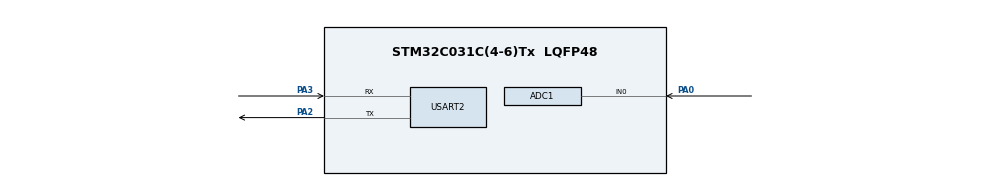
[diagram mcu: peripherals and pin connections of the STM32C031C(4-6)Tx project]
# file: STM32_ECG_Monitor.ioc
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ADC1.NbrOfConversionFlag=0
ADC1.SamplingTimeCommon1=ADC_SAMPLETIME_12CYCLES_5
ADC1.SelectedChannel=ADC_CHANNEL_0
ADC1.master=1
Mcu.Family=STM32C0
Mcu.Name=STM32C031C(4-6)Tx
Mcu.Package=LQFP48
NVIC.TIM3_IRQn=true\:0\:0\:false\:false\:true\:true\:true\:true
PA0.Mode=IN0
PA0.Signal=ADC1_IN0
PA2.Mode=Asynchronous
PA2.Signal=USART2_TX
PA3.Mode=Asynchronous
PA3.Signal=USART2_RX
ProjectManager.HeapSize=0x200
ProjectManager.StackSize=0x400
ProjectManager.TargetToolchain=STM32CubeIDE
RCC.ADCFreq_Value=12000000
RCC.AHBFreq_Value=12000000
RCC.CortexFreq_Value=12000000
RCC.EXTERNAL_CLOCK_VALUE=12288000
RCC.HCLKFreq_Value=12000000
RCC.HSE_VALUE=8000000
RCC.HSI_VALUE=48000000
RCC.LSE_VALUE=32768
RCC.SYSCLKFreq_VALUE=12000000
TIM3.Period=999
TIM3.Prescaler=47
USART2.VirtualMode-Asynchronous=VM_ASYNC
VP_TIM3_VS_ClockSourceINT.Mode=Internal
board=custom

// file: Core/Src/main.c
/* USER CODE BEGIN Header */
/**
  ******************************************************************************
  * @file           : main.c
  * @brief          : Main program body
  ******************************************************************************
  * @attention
  *
  * Copyright (c) 2026 STMicroelectronics.
  * All rights reserved.
  *
  * This software is licensed under terms that can be found in the LICENSE file
  * in the root directory of this software component.
  * If no LICENSE file comes with this software, it is provided AS-IS.
  *
  ******************************************************************************
  */
/* USER CODE END Header */
#include "main.h"

/* USER CODE BEGIN Includes */
#include <stdio.h>
/* USER CODE END Includes */

ADC_HandleTypeDef hadc1;

TIM_HandleTypeDef htim3;

UART_HandleTypeDef huart2;

/* USER CODE BEGIN PV */

/* USER CODE BEGIN PV */

/* USER CODE BEGIN PV */

volatile uint16_t adc_value = 0;
volatile uint8_t sample_ready = 0;

char uart_buffer[32];
int uart_length;

/* USER CODE END PV */

/* USER CODE END PV */

/* USER CODE END PV */

void SystemClock_Config(void);
static void MX_GPIO_Init(void);
static void MX_ADC1_Init(void);
static void MX_TIM3_Init(void);
static void MX_USART2_UART_Init(void);

int main(void)
{

  /* MCU Configuration--------------------------------------------------------*/

  /* Reset of all peripherals, Initializes the Flash interface and the Systick. */
  HAL_Init();

  /* Configure the system clock */
  SystemClock_Config();

  /* Initialize all configured peripherals */
  MX_GPIO_Init();
  MX_ADC1_Init();
  MX_TIM3_Init();
  MX_USART2_UART_Init();
  /* USER CODE BEGIN 2 */

  HAL_TIM_Base_Start_IT(&htim3);

  /* USER CODE END 2 */

  /* Infinite loop */
  while (1)
  {

      /* USER CODE BEGIN 3 */

      if (sample_ready)
      {
          sample_ready = 0;

          HAL_ADC_Start(&hadc1);

          if (HAL_ADC_PollForConversion(&hadc1, 10) == HAL_OK)
          {
              adc_value = HAL_ADC_GetValue(&hadc1);
              uart_length = snprintf(uart_buffer,
                                     sizeof(uart_buffer),
                                     "%u\r\n",
                                     adc_value);

              HAL_UART_Transmit(&huart2,
                                (uint8_t *)uart_buffer,
                                uart_length,
                                HAL_MAX_DELAY);
          }

          HAL_ADC_Stop(&hadc1);
      }
  }
}

void SystemClock_Config(void)
{
  RCC_OscInitTypeDef RCC_OscInitStruct = {0};
  RCC_ClkInitTypeDef RCC_ClkInitStruct = {0};

  __HAL_FLASH_SET_LATENCY(FLASH_LATENCY_0);

  /** Initializes the RCC Oscillators according to the specified parameters
  * in the RCC_OscInitTypeDef structure.
  */
  RCC_OscInitStruct.OscillatorType = RCC_OSCILLATORTYPE_HSI;
  RCC_OscInitStruct.HSIState = RCC_HSI_ON;
  RCC_OscInitStruct.HSIDiv = RCC_HSI_DIV4;
  RCC_OscInitStruct.HSICalibrationValue = RCC_HSICALIBRATION_DEFAULT;
  if (HAL_RCC_OscConfig(&RCC_OscInitStruct) != HAL_OK)
  {
    Error_Handler();
  }

  /** Initializes the CPU, AHB and APB buses clocks
  */
  RCC_ClkInitStruct.ClockType = RCC_CLOCKTYPE_HCLK|RCC_CLOCKTYPE_SYSCLK
                              |RCC_CLOCKTYPE_PCLK1;
  RCC_ClkInitStruct.SYSCLKSource = RCC_SYSCLKSOURCE_HSI;
  RCC_ClkInitStruct.SYSCLKDivider = RCC_SYSCLK_DIV1;
  RCC_ClkInitStruct.AHBCLKDivider = RCC_HCLK_DIV1;
  RCC_ClkInitStruct.APB1CLKDivider = RCC_APB1_DIV1;

  if (HAL_RCC_ClockConfig(&RCC_ClkInitStruct, FLASH_LATENCY_0) != HAL_OK)
  {
    Error_Handler();
  }
}

static void MX_ADC1_Init(void)
{

  ADC_ChannelConfTypeDef sConfig = {0};

  /** Configure the global features of the ADC (Clock, Resolution, Data Alignment and number of conversion)
  */
  hadc1.Instance = ADC1;
  hadc1.Init.ClockPrescaler = ADC_CLOCK_SYNC_PCLK_DIV1;
  hadc1.Init.Resolution = ADC_RESOLUTION_12B;
  hadc1.Init.DataAlign = ADC_DATAALIGN_RIGHT;
  hadc1.Init.ScanConvMode = ADC_SCAN_SEQ_FIXED;
  hadc1.Init.EOCSelection = ADC_EOC_SINGLE_CONV;
  hadc1.Init.LowPowerAutoWait = DISABLE;
  hadc1.Init.LowPowerAutoPowerOff = DISABLE;
  hadc1.Init.ContinuousConvMode = DISABLE;
  hadc1.Init.NbrOfConversion = 1;
  hadc1.Init.DiscontinuousConvMode = DISABLE;
  hadc1.Init.ExternalTrigConv = ADC_SOFTWARE_START;
  hadc1.Init.ExternalTrigConvEdge = ADC_EXTERNALTRIGCONVEDGE_NONE;
  hadc1.Init.DMAContinuousRequests = DISABLE;
  hadc1.Init.Overrun = ADC_OVR_DATA_PRESERVED;
  hadc1.Init.SamplingTimeCommon1 = ADC_SAMPLETIME_12CYCLES_5;
  hadc1.Init.OversamplingMode = DISABLE;
  hadc1.Init.TriggerFrequencyMode = ADC_TRIGGER_FREQ_HIGH;
  if (HAL_ADC_Init(&hadc1) != HAL_OK)
  {
    Error_Handler();
  }

  /** Configure Regular Channel
  */
  sConfig.Channel = ADC_CHANNEL_0;
  sConfig.Rank = ADC_RANK_CHANNEL_NUMBER;
  if (HAL_ADC_ConfigChannel(&hadc1, &sConfig) != HAL_OK)
  {
    Error_Handler();
  }

}

static void MX_TIM3_Init(void)
{

  TIM_ClockConfigTypeDef sClockSourceConfig = {0};
  TIM_MasterConfigTypeDef sMasterConfig = {0};

  htim3.Instance = TIM3;
  htim3.Init.Prescaler = 47;
  htim3.Init.CounterMode = TIM_COUNTERMODE_UP;
  htim3.Init.Period = 999;
  htim3.Init.ClockDivision = TIM_CLOCKDIVISION_DIV1;
  htim3.Init.AutoReloadPreload = TIM_AUTORELOAD_PRELOAD_DISABLE;
  if (HAL_TIM_Base_Init(&htim3) != HAL_OK)
  {
    Error_Handler();
  }
  sClockSourceConfig.ClockSource = TIM_CLOCKSOURCE_INTERNAL;
  if (HAL_TIM_ConfigClockSource(&htim3, &sClockSourceConfig) != HAL_OK)
  {
    Error_Handler();
  }
  sMasterConfig.MasterOutputTrigger = TIM_TRGO_RESET;
  sMasterConfig.MasterSlaveMode = TIM_MASTERSLAVEMODE_DISABLE;
  if (HAL_TIMEx_MasterConfigSynchronization(&htim3, &sMasterConfig) != HAL_OK)
  {
    Error_Handler();
  }

}

static void MX_USART2_UART_Init(void)
{

  huart2.Instance = USART2;
  huart2.Init.BaudRate = 115200;
  huart2.Init.WordLength = UART_WORDLENGTH_8B;
  huart2.Init.StopBits = UART_STOPBITS_1;
  huart2.Init.Parity = UART_PARITY_NONE;
  huart2.Init.Mode = UART_MODE_TX_RX;
  huart2.Init.HwFlowCtl = UART_HWCONTROL_NONE;
  huart2.Init.OverSampling = UART_OVERSAMPLING_16;
  huart2.Init.OneBitSampling = UART_ONE_BIT_SAMPLE_DISABLE;
  huart2.Init.ClockPrescaler = UART_PRESCALER_DIV1;
  huart2.AdvancedInit.AdvFeatureInit = UART_ADVFEATURE_NO_INIT;
  if (HAL_UART_Init(&huart2) != HAL_OK)
  {
    Error_Handler();
  }

}

static void MX_GPIO_Init(void)
{

  /* GPIO Ports Clock Enable */
  __HAL_RCC_GPIOA_CLK_ENABLE();

}

/* USER CODE BEGIN 4 */

void HAL_TIM_PeriodElapsedCallback(TIM_HandleTypeDef *htim)
{
    if (htim->Instance == TIM3)
    {
        sample_ready = 1;
    }
}

/* USER CODE END 4 */

void Error_Handler(void)
{
  __disable_irq();
  while (1)
  {
  }
}
